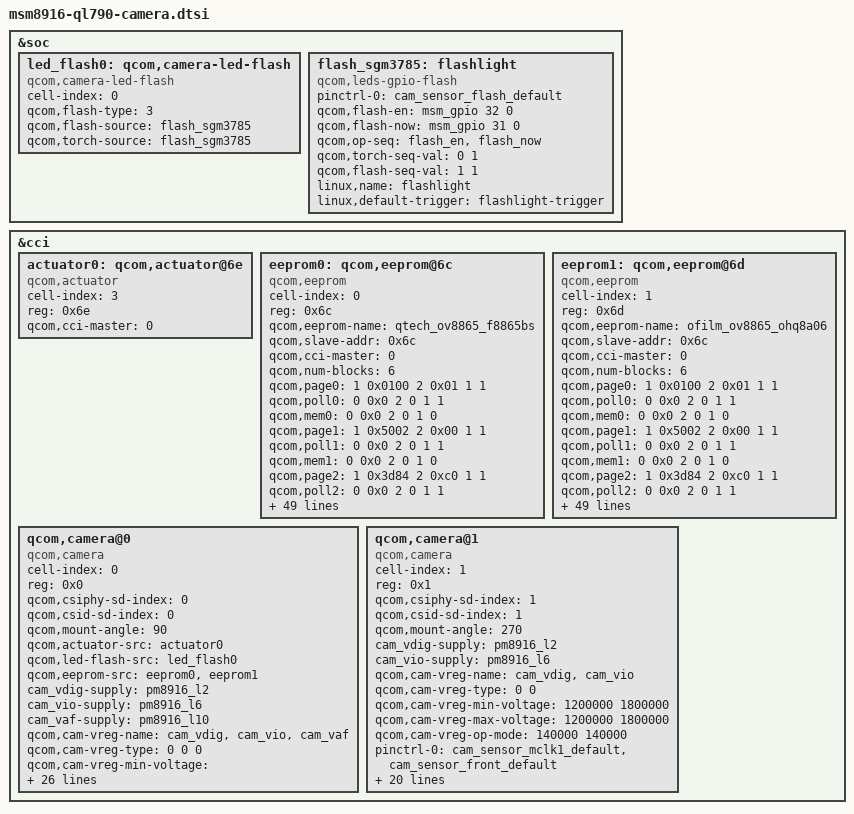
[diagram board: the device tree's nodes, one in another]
/*
 * Copyright (c) 2014, The Linux Foundation. All rights reserved.
 *
 * This program is free software; you can redistribute it and/or modify
 * it under the terms of the GNU General Public License version 2 and
 * only version 2 as published by the Free Software Foundation.
 *
 * This program is distributed in the hope that it will be useful,
 * but WITHOUT ANY WARRANTY; without even the implied warranty of
 * MERCHANTABILITY or FITNESS FOR A PARTICULAR PURPOSE.  See the
 * GNU General Public License for more details.
 */
&soc {

	led_flash0: qcom,camera-led-flash {
		cell-index = <0>;
		compatible = "qcom,camera-led-flash";
		qcom,flash-type = <3>;
		qcom,flash-source = <&flash_sgm3785>;
		qcom,torch-source = <&flash_sgm3785>;
	};

	flash_sgm3785:flashlight {
		compatible = "qcom,leds-gpio-flash";
		status = "okay";
		pinctrl-names = "flash_default";
		pinctrl-0 = <&cam_sensor_flash_default>;
		qcom,flash-en = <&msm_gpio 32 0>;
		qcom,flash-now = <&msm_gpio 31 0>;
		qcom,op-seq = "flash_en", "flash_now";
		qcom,torch-seq-val = <0 1>;
		qcom,flash-seq-val = <1 1>;
		linux,name = "flashlight";
		linux,default-trigger = "flashlight-trigger";
	};

};

&cci {

	actuator0: qcom,actuator@6e {
		cell-index = <3>;
		reg = <0x6e>;
		compatible = "qcom,actuator";
		qcom,cci-master = <0>;
	};

	eeprom0: qcom,eeprom@6c {
		cell-index = <0>;
		reg = <0x6c>;
		qcom,eeprom-name = "qtech_ov8865_f8865bs";
		compatible = "qcom,eeprom";
		qcom,slave-addr = <0x6c>;
		qcom,cci-master = <0>;
		qcom,num-blocks = <6>;

		qcom,page0 = <1 0x0100 2 0x01 1 1>;
		qcom,poll0 = <0 0x0 2 0 1 1>;
		qcom,mem0 = <0 0x0 2 0 1 0>;

		qcom,page1 = <1 0x5002 2 0x00 1 1>;
		qcom,poll1 = <0 0x0 2 0 1 1>;
		qcom,mem1 = <0 0x0 2 0 1 0>;

		qcom,page2 = <1 0x3d84 2 0xc0 1 1>;
		qcom,poll2 = <0 0x0 2 0 1 1>;
		qcom,mem2 = <0 0x3d00 2 0 1 0>;

		qcom,page3 = <1 0x3d88 2 0x7010 2 1>;
		qcom,poll3 = <0 0x0 2 0 1 1>;
		qcom,mem3 = <0 0x3d00 2 0 1 0>;

		qcom,page4 = <1 0x3d8A 2 0x7115 2 1>;
		qcom,pageen4 = <1 0x3d81 2 0x01 1 10>;
		qcom,poll4 = <0 0x0 2 0 1 1>;
		qcom,mem4 = <262 0x7010 2 0 1 1>;

		qcom,page5 = <1 0x5002 2 0x08 1 1>;
		qcom,poll5 = <0 0x0 2 0 1 1>;
		qcom,mem5 = <0 0x0 2 0 1 0>;

		cam_vdig-supply = <&pm8916_l2>;
		cam_vio-supply = <&pm8916_l6>;
		qcom,cam-vreg-name = "cam_vdig", "cam_vio";
		qcom,cam-vreg-type = <0 1>;
		qcom,cam-vreg-min-voltage = <1200000 1800000>;
		qcom,cam-vreg-max-voltage = <1200000 1800000>;
		qcom,cam-vreg-op-mode = <140000 140000>;
		pinctrl-names = "cam_default", "cam_suspend";
		pinctrl-0 = <&cam_sensor_mclk0_default
				&cam_sensor_rear_default>;
		pinctrl-1 = <&cam_sensor_mclk0_sleep &cam_sensor_rear_sleep>;
		qcom,gpio-no-mux = <0>;
		gpios = <&msm_gpio 26 0>,
				<&msm_gpio 35 0>,
				<&msm_gpio 34 0>,
				<&msm_gpio 51 0>,
				<&msm_gpio 121 0>,
				<&msm_gpio 120 0>;
		qcom,gpio-reset = <1>;
		qcom,gpio-standby = <2>;
		qcom,gpio-cameraid = <3>;
		qcom,gpio-vana = <4>;
		qcom,gpio-vdig = <5>;
		qcom,gpio-req-tbl-num = <0 1 2 3 4 5>;
		qcom,gpio-req-tbl-flags = <1 0 0 1 0 0>;
		qcom,gpio-req-tbl-label = "CAMIF_MCLK",
					"CAM_RESET",
					"CAM_STANDBY",
					"CAM_ID",
					"CAM_VANA",
					"CAM_VDIG";
		qcom,cam-power-seq-type = "sensor_gpio",
					  "sensor_gpio",
					  "sensor_vreg",
					  "sensor_gpio",
					  "sensor_vreg",
					  "sensor_gpio",
					  "sensor_gpio",
					  "sensor_gpio",
					  "sensor_clk",
					  "sensor_i2c_mux";
		qcom,cam-power-seq-val = "sensor_gpio_standby",
					 "sensor_gpio_reset",
					 "cam_vio",
					 "sensor_gpio_vana",
					 "cam_vdig",
					 "sensor_gpio_vdig",
					 "sensor_gpio_standby",
					 "sensor_gpio_reset",
					 "sensor_cam_mclk",
					 "none";
		qcom,cam-power-seq-cfg-val = <0 0 0 1 0 0 1 1 23880000 0>;
		qcom,cam-power-seq-delay = <0 0 1 1 1 1 1 1 10 0>;
		clocks = <&clock_gcc clk_mclk0_clk_src>,
				<&clock_gcc clk_gcc_camss_mclk0_clk>;
		clock-names = "cam_src_clk", "cam_clk";
	};

	eeprom1: qcom,eeprom@6d {
		cell-index = <1>;
		reg = <0x6d>;
		qcom,eeprom-name = "ofilm_ov8865_ohq8a06";
		compatible = "qcom,eeprom";
		qcom,slave-addr = <0x6c>;
		qcom,cci-master = <0>;
		qcom,num-blocks = <6>;

		qcom,page0 = <1 0x0100 2 0x01 1 1>;
		qcom,poll0 = <0 0x0 2 0 1 1>;
		qcom,mem0 = <0 0x0 2 0 1 0>;

		qcom,page1 = <1 0x5002 2 0x00 1 1>;
		qcom,poll1 = <0 0x0 2 0 1 1>;
		qcom,mem1 = <0 0x0 2 0 1 0>;

		qcom,page2 = <1 0x3d84 2 0xc0 1 1>;
		qcom,poll2 = <0 0x0 2 0 1 1>;
		qcom,mem2 = <0 0x3d00 2 0 1 0>;

		qcom,page3 = <1 0x3d88 2 0x7010 2 1>;
		qcom,poll3 = <0 0x0 2 0 1 1>;
		qcom,mem3 = <0 0x3d00 2 0 1 0>;

		qcom,page4 = <1 0x3d8A 2 0x70F4 2 1>;
		qcom,pageen4 = <1 0x3d81 2 0x01 1 10>;
		qcom,poll4 = <0 0x0 2 0 1 1>;
		qcom,mem4 = <229 0x7010 2 0 1 1>;

		qcom,page5 = <1 0x5002 2 0x08 1 1>;
		qcom,poll5 = <0 0x0 2 0 1 1>;
		qcom,mem5 = <0 0x0 2 0 1 0>;

		cam_vdig-supply = <&pm8916_l2>;
		cam_vio-supply = <&pm8916_l6>;
		qcom,cam-vreg-name = "cam_vdig", "cam_vio";
		qcom,cam-vreg-type = <0 1>;
		qcom,cam-vreg-min-voltage = <1200000 1800000>;
		qcom,cam-vreg-max-voltage = <1200000 1800000>;
		qcom,cam-vreg-op-mode = <140000 140000>;
		pinctrl-names = "cam_default", "cam_suspend";
		pinctrl-0 = <&cam_sensor_mclk0_default
			&cam_sensor_rear_default>;
		pinctrl-1 = <&cam_sensor_mclk0_sleep &cam_sensor_rear_sleep>;
		qcom,gpio-no-mux = <0>;
		gpios = <&msm_gpio 26 0>,
			<&msm_gpio 35 0>,
			<&msm_gpio 34 0>,
			<&msm_gpio 51 0>,
			<&msm_gpio 121 0>,
			<&msm_gpio 120 0>;
		qcom,gpio-reset = <1>;
		qcom,gpio-standby = <2>;
		qcom,gpio-cameraid = <3>;
		qcom,gpio-vana = <4>;
		qcom,gpio-vdig = <5>;
		qcom,gpio-req-tbl-num = <0 1 2 3 4 5>;
		qcom,gpio-req-tbl-flags = <1 0 0 1 0 0>;
		qcom,gpio-req-tbl-label = "CAMIF_MCLK",
					"CAM_RESET",
					"CAM_STANDBY",
					"CAM_ID",
					"CAM_VANA",
					"CAM_VDIG";
		qcom,cam-power-seq-type = "sensor_gpio",
					"sensor_gpio",
					"sensor_vreg",
					"sensor_gpio",
					"sensor_vreg",
					"sensor_gpio",
					"sensor_gpio",
					"sensor_gpio",
					"sensor_clk",
					"sensor_i2c_mux";
		qcom,cam-power-seq-val = "sensor_gpio_standby",
					"sensor_gpio_reset",
					"cam_vio",
					"sensor_gpio_vana",
					"cam_vdig",
					"sensor_gpio_vdig",
					"sensor_gpio_standby",
					"sensor_gpio_reset",
					"sensor_cam_mclk",
					 "none";
		qcom,cam-power-seq-cfg-val = <0 0 0 1 0 0 1 1 23880000 0>;
		qcom,cam-power-seq-delay = <0 0 1 1 1 1 1 1 10 0>;
		clocks = <&clock_gcc clk_mclk0_clk_src>,
			<&clock_gcc clk_gcc_camss_mclk0_clk>;
		clock-names = "cam_src_clk", "cam_clk";
	};

	qcom,camera@0 {
		cell-index = <0>;
		compatible = "qcom,camera";
		reg = <0x0>;
		qcom,csiphy-sd-index = <0>;
		qcom,csid-sd-index = <0>;
		qcom,mount-angle = <90>;
		qcom,actuator-src = <&actuator0>;
		qcom,led-flash-src = <&led_flash0>;
		qcom,eeprom-src = <&eeprom0 &eeprom1>;
		cam_vdig-supply = <&pm8916_l2>;
		cam_vio-supply = <&pm8916_l6>;
		cam_vaf-supply = <&pm8916_l10>;
		qcom,cam-vreg-name = "cam_vdig", "cam_vio", "cam_vaf";
		qcom,cam-vreg-type = <0 0 0>;
		qcom,cam-vreg-min-voltage = <1200000 1800000 2700000>;
		qcom,cam-vreg-max-voltage = <1200000 1800000 2800000>;
		qcom,cam-vreg-op-mode = <140000 140000 140000>;
		pinctrl-names = "cam_default", "cam_suspend";
		pinctrl-0 = <&cam_sensor_mclk0_default
			&cam_sensor_rear_default>;
		pinctrl-1 = <&cam_sensor_mclk0_sleep &cam_sensor_rear_sleep>;
		gpios = <&msm_gpio 26 0>,
			<&msm_gpio 35 0>,
			<&msm_gpio 34 0>,
			<&msm_gpio 51 0>,
			<&msm_gpio 121 0>,
			<&msm_gpio 120 0>;
		qcom,gpio-reset = <1>;
		qcom,gpio-standby = <2>;
		qcom,gpio-cameraid = <3>;
		qcom,gpio-vana = <4>;
		qcom,gpio-vdig = <5>;
		qcom,gpio-req-tbl-num = <0 1 2 3 4 5>;
		qcom,gpio-req-tbl-flags = <1 0 0 1 0 0>;
		qcom,gpio-req-tbl-label = "CAMIF_MCLK",
					"CAM_RESET",
					"CAM_STANDBY",
					"CAM_ID",
					"CAM_VANA",
					"CAM_VDIG";
		qcom,sensor-position = <0>;
		qcom,sensor-mode = <0>;
		qcom,cci-master = <0>;
		qcom,mclk-23880000;
		status = "ok";
		clocks = <&clock_gcc clk_mclk0_clk_src>,
			<&clock_gcc clk_gcc_camss_mclk0_clk>;
		clock-names = "cam_src_clk", "cam_clk";
	};

	qcom,camera@1 {
		cell-index = <1>;
		compatible = "qcom,camera";
		reg = <0x1>;
		qcom,csiphy-sd-index = <1>;
		qcom,csid-sd-index = <1>;
		qcom,mount-angle = <270>;
		cam_vdig-supply = <&pm8916_l2>;
		cam_vio-supply = <&pm8916_l6>;
		qcom,cam-vreg-name = "cam_vdig", "cam_vio";
		qcom,cam-vreg-type = <0 0>;
		qcom,cam-vreg-min-voltage = <1200000 1800000>;
		qcom,cam-vreg-max-voltage = <1200000 1800000>;
		qcom,cam-vreg-op-mode = <140000 140000>;
		pinctrl-names = "cam_default", "cam_suspend";
		pinctrl-0 = <&cam_sensor_mclk1_default &cam_sensor_front_default>;
		pinctrl-1 = <&cam_sensor_mclk1_sleep &cam_sensor_front_sleep>;
		gpios = <&msm_gpio 27 0>,
			<&msm_gpio 28 0>,
			<&msm_gpio 33 0>,
			<&msm_gpio 50 0>,
			<&msm_gpio 121 0>,
			<&msm_gpio 120 0>;
		qcom,gpio-reset = <1>;
		qcom,gpio-standby = <2>;
		qcom,gpio-cameraid = <3>;
		qcom,gpio-vana = <4>;
		qcom,gpio-vdig = <5>;
		qcom,gpio-req-tbl-num = <0 1 2 3 4 5>;
		qcom,gpio-req-tbl-flags = <1 0 0 1 0 0>;
		qcom,gpio-req-tbl-label = "CAMIF_MCLK",
					"CAM_RESET",
					"CAM_STANDBY",
					"CAM_ID",
					"CAM_VANA",
					"CAM_VDIG";
		qcom,sensor-position = <1>;
		qcom,sensor-mode = <0>;
		qcom,cci-master = <0>;
		qcom,mclk-23880000;
		status = "ok";
		clocks = <&clock_gcc clk_mclk1_clk_src>,
			<&clock_gcc clk_gcc_camss_mclk1_clk>;
		clock-names = "cam_src_clk", "cam_clk";
	};
};

